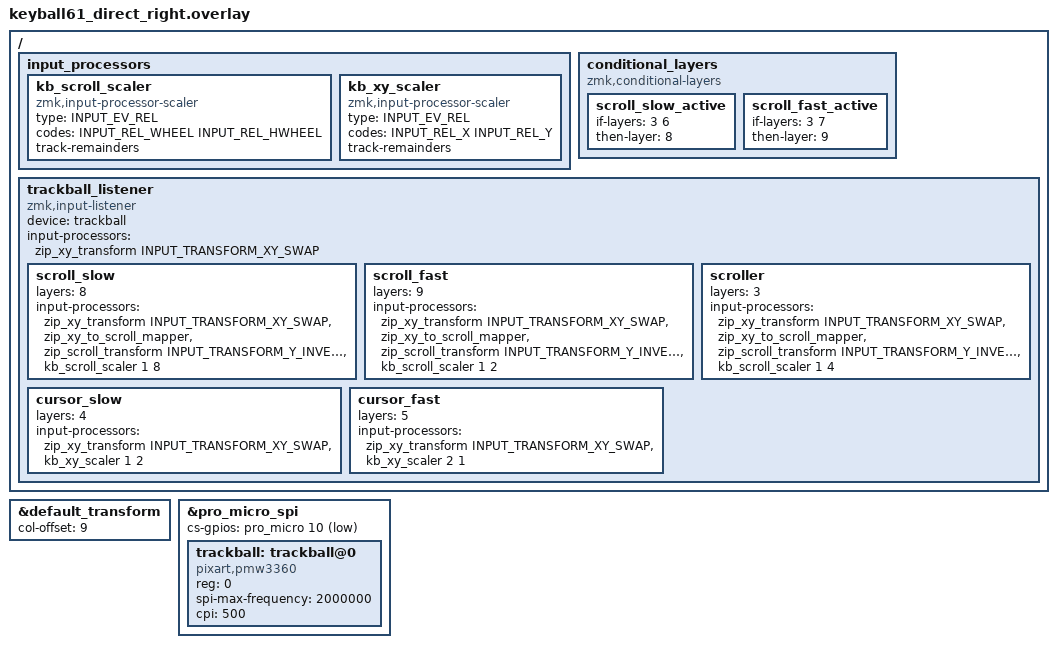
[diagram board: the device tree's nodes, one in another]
/*
 * Правая половина Keyball61 БЕЗ донгла: она сама подключается к компьютеру
 * (по USB или Bluetooth) и является главным устройством (central).
 * Левая половина подключается к правой. Для левой используется обычная
 * сборка keyball61_left.
 *   NCS  -> Pro Micro D10  (P0.09)
 *   MOSI -> Pro Micro D16  (P0.10)
 *   MISO -> Pro Micro D14  (P1.11)
 *   SCLK -> Pro Micro D15  (P1.13)
 */

#include "keyball61.dtsi"
#include <input/processors.dtsi>
#include <dt-bindings/zmk/input_transform.h>
#include <zephyr/dt-bindings/input/input-event-codes.h>

/* Ключи правой половины идут в карте после ключей левой */
&default_transform {
    col-offset = <9>;
};

&pro_micro_spi {
    status = "okay";
    cs-gpios = <&pro_micro 10 GPIO_ACTIVE_LOW>;

    trackball: trackball@0 {
        compatible = "pixart,pmw3360";
        reg = <0>;
        spi-max-frequency = <2000000>;
        cpi = <500>;
    };
};

/ {
    input_processors {
        /* Масштабирование прокрутки с накоплением остатка (плавный скролл) */
        kb_scroll_scaler: kb_scroll_scaler {
            compatible = "zmk,input-processor-scaler";
            #input-processor-cells = <2>;
            type = <INPUT_EV_REL>;
            codes = <INPUT_REL_WHEEL INPUT_REL_HWHEEL>;
            track-remainders;
        };

        /* Масштабирование курсора с накоплением остатка */
        kb_xy_scaler: kb_xy_scaler {
            compatible = "zmk,input-processor-scaler";
            #input-processor-cells = <2>;
            type = <INPUT_EV_REL>;
            codes = <INPUT_REL_X INPUT_REL_Y>;
            track-remainders;
        };
    };

    /* Слои-флаги скорости прокрутки + слой 3 (режим прокрутки) = слои 8 и 9 */
    conditional_layers {
        compatible = "zmk,conditional-layers";

        scroll_slow_active {
            if-layers = <3 6>;
            then-layer = <8>;
        };

        scroll_fast_active {
            if-layers = <3 7>;
            then-layer = <9>;
        };
    };

    /*
     * Правила проверяются сверху вниз, срабатывает первое подошедшее.
     * Слои: 3 = прокрутка (удерживается), 4/5 = курсор медленнее/быстрее,
     *       6/7 = прокрутка медленнее/быстрее, 8/9 = служебные.
     * Оси датчика повёрнуты на 90 градусов: в каждом правиле сначала меняем X и Y местами.
     * Обычный курсор (ни одно правило не подошло): только обмен осей.
     */
    trackball_listener: trackball_listener {
        compatible = "zmk,input-listener";
        device = <&trackball>;
        input-processors = <&zip_xy_transform INPUT_TRANSFORM_XY_SWAP>;

        scroll_slow {
            layers = <8>;
            input-processors = <&zip_xy_transform INPUT_TRANSFORM_XY_SWAP
                                &zip_xy_to_scroll_mapper
                                &zip_scroll_transform INPUT_TRANSFORM_Y_INVERT
                                &kb_scroll_scaler 1 8>;
        };

        scroll_fast {
            layers = <9>;
            input-processors = <&zip_xy_transform INPUT_TRANSFORM_XY_SWAP
                                &zip_xy_to_scroll_mapper
                                &zip_scroll_transform INPUT_TRANSFORM_Y_INVERT
                                &kb_scroll_scaler 1 2>;
        };

        scroller {
            layers = <3>;
            input-processors = <&zip_xy_transform INPUT_TRANSFORM_XY_SWAP
                                &zip_xy_to_scroll_mapper
                                &zip_scroll_transform INPUT_TRANSFORM_Y_INVERT
                                &kb_scroll_scaler 1 4>;
        };

        cursor_slow {
            layers = <4>;
            input-processors = <&zip_xy_transform INPUT_TRANSFORM_XY_SWAP
                                &kb_xy_scaler 1 2>;
        };

        cursor_fast {
            layers = <5>;
            input-processors = <&zip_xy_transform INPUT_TRANSFORM_XY_SWAP
                                &kb_xy_scaler 2 1>;
        };
    };
};
